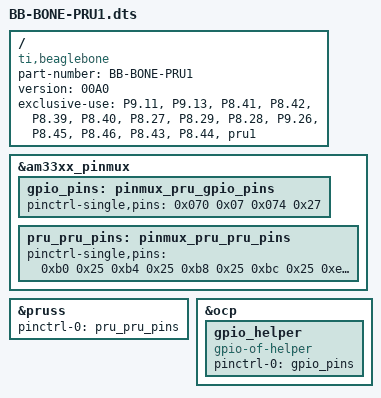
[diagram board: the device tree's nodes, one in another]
/dts-v1/;
/plugin/;

/ {
        compatible = "ti,beaglebone", "ti,beaglebone-black";
        part-number = "BB-BONE-PRU1";
        version = "00A0";
        exclusive-use = "P9.11",
                        "P9.13",
                        //"P8.21", //this pin appears to conflict with the eMMC
                        //"P8.20", //this pin appears to conflict with the eMMC
                        "P8.41",
                        "P8.42",
                        "P8.39",
                        "P8.40",
                        "P8.27",
                        "P8.29",
                        "P8.28",
                        "P9.26",
                        "P8.45",
                        "P8.46",
                        "P8.43",
                        "P8.44",
                        "pru1";

        fragment@0 {
                target = <&am33xx_pinmux>;
                __overlay__ {

                        gpio_pins: pinmux_pru_gpio_pins {
                                pinctrl-single,pins = <0x070 0x07  //P9_11 MODE7 GPIO output pull-down
                                                       0x074 0x27  //P9_13 MODE7 GPIO input pull-down
                                                      >;
                        };

                        pru_pru_pins: pinmux_pru_pru_pins {
                                pinctrl-single,pins = <// 0x80 0x25 //this pin appears to conflict with the eMMC
                                                       // 0x84 0x25 //this pin appears to conflict with the eMMC
                                                       0xb0 0x25  //P8_41 input pull-down
                                                       0xb4 0x25  //P8_42 input pull-down
                                                       0xb8 0x25  //P8_39 input pull-down
                                                       0xbc 0x25  //P8_40 input pull-down
                                                       0xe0 0x25  //P8_27 input pull-down
                                                       0xe4 0x25  //P8_29 input pull-down
                                                       0xe8 0x25  //P8_28 input pull-down
                                                       0x180 0x06 //P9_26 input pull-down
                                                       0xa0 0x05  //P8_45 output
                                                       0xa4 0x05  //P8_46 output
                                                       0xa8 0x05  //P8_43 output
                                                       0xac 0x05  //P8_44 output
                                                       >;
                                                                               };
                };
        };
        fragment@1 {
                target = <&pruss>;
                __overlay__ {
                        status = "okay";
                        pinctrl-names = "default";
                        pinctrl-0 = <&pru_pru_pins>;
                };
        };

       fragment@2 {         // Enable the GPIOs
                target = <&ocp>;
                __overlay__ {
                  gpio_helper {
                        compatible = "gpio-of-helper";
                        status = "okay";
                        pinctrl-names = "default";
                        pinctrl-0 = <&gpio_pins>;
                };
        };
   };
};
